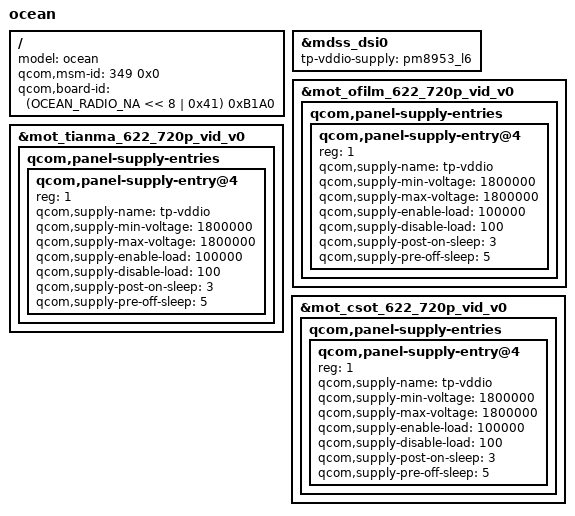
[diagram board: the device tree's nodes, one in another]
/* Copyright (c) 2018, The Linux Foundation. All rights reserved.
 *
 * This program is free software; you can redistribute it and/or modify
 * it under the terms of the GNU General Public License version 2 and
 * only version 2 as published by the Free Software Foundation.
 *
 * This program is distributed in the hope that it will be useful,
 * but WITHOUT ANY WARRANTY; without even the implied warranty of
 * MERCHANTABILITY or FITNESS FOR A PARTICULAR PURPOSE.  See the
 * GNU General Public License for more details.
 */

/dts-v1/;
/plugin/;

#include <dt-bindings/clock/msm-clocks-8953.h>

#include "sdm632-ocean-common-overlay.dtsi"
#include "sdm632-ocean-na-common-overlay.dtsi"

/ {
	model = "ocean";
	qcom,msm-id = <349 0x0>;
	qcom,board-id = <(OCEAN_RADIO_NA << 8 | 0x41) 0xB1A0>;
};

&mdss_dsi0 {
	tp-vddio-supply = <&pm8953_l6>;
};

&mot_ofilm_622_720p_vid_v0 {
	qcom,panel-supply-entries {
		qcom,panel-supply-entry@4 {
			reg = <1>;
			qcom,supply-name = "tp-vddio";
			qcom,supply-min-voltage = <1800000>;
			qcom,supply-max-voltage = <1800000>;
			qcom,supply-enable-load = <100000>;
			qcom,supply-disable-load = <100>;
			qcom,supply-post-on-sleep = <3>;
			qcom,supply-pre-off-sleep = <5>;
		};
	};
};

&mot_tianma_622_720p_vid_v0 {
	qcom,panel-supply-entries {
		qcom,panel-supply-entry@4 {
			reg = <1>;
			qcom,supply-name = "tp-vddio";
			qcom,supply-min-voltage = <1800000>;
			qcom,supply-max-voltage = <1800000>;
			qcom,supply-enable-load = <100000>;
			qcom,supply-disable-load = <100>;
			qcom,supply-post-on-sleep = <3>;
			qcom,supply-pre-off-sleep = <5>;
		};
	};
};

&mot_csot_622_720p_vid_v0 {
	qcom,panel-supply-entries {
		qcom,panel-supply-entry@4 {
			reg = <1>;
			qcom,supply-name = "tp-vddio";
			qcom,supply-min-voltage = <1800000>;
			qcom,supply-max-voltage = <1800000>;
			qcom,supply-enable-load = <100000>;
			qcom,supply-disable-load = <100>;
			qcom,supply-post-on-sleep = <3>;
			qcom,supply-pre-off-sleep = <5>;
		};
	};
};
